# ATSAMG54x19 register map
Vendor: Atmel; Series: SAMG54; File version: 0
Atmel ATSAMG54x19 Microcontroller
CPU: CM4 r0p1, selectable endian, MPU, FPU, 4 interrupt priority bits
Registers are 32-bit, read-write, reset 0x0 unless marked. A register's access mark holds for its fields unless they carry their own. Offsets are from the block's base; lines under a group give offsets from that group; [hi:lo] are bit positions; {n}, {i} and the like mark numbered series; 'fields as' and 'values as' point back to an identical list; <NAME> marks a mode.

## Memory map
0x40000000 I2SC0 size 0x4000 — Inter-IC Sound Controller 0
0x40004000 I2SC1 size 0x4000 — Inter-IC Sound Controller 1
0x40008000 SPI size 0x4000 — Serial Peripheral Interface
0x4000D000 MPU size 0x830 — Memory Protection Unit (MPU)
0x40010000 TC0 size 0x4000 — Timer Counter 0
0x40014000 TC1 size 0x4000 — Timer Counter 1
0x40018000 TWI0 size 0x4000 — Two-wire Interface High Speed
0x4001C000 TWI1 size 0x4000 — Two-wire Interface 1
0x40024000 USART size 0x4000 — Universal Synchronous Asynchronous Receiver Transmitter
0x40028000 MEM2MEM size 0x4000 — Memory to Memory
0x4002C000 PDMIC0 size 0x4000 — Pulse Density Modulation Interface Controller 0
0x40030000 PDMIC1 size 0x4000 — Pulse Density Modulation Interface Controller 1
0x40038000 ADC size 0x4000 — Analog-to-Digital Converter
0x40040000 TWI2 size 0x4000 — Two-wire Interface 2
0x400E0200 MATRIX size 0x200 — AHB Bus Matrix
0x400E0400 PMC size 0x140 — Power Management Controller
0x400E0600 UART0 size 0x128 — Universal Asynchronous Receiver Transmitter 0
0x400E0740 CHIPID size 0x200 — Chip Identifier
0x400E0800 UART1 size 0x128 — Universal Asynchronous Receiver Transmitter 1
0x400E0A00 EFC size 0x200 — Embedded Flash Controller
0x400E0E00 PIOA size 0x200 — Parallel Input/Output Controller A
0x400E1000 PIOB size 0x200 — Parallel Input/Output Controller B
0x400E1400 RSTC size 0x200 — Reset Controller
0x400E1410 SUPC size 0x200 — Supply Controller
0x400E1430 RTT size 0x200 — Real-time Timer
0x400E1450 WDT size 0x200 — Watchdog Timer
0x400E1460 RTC size 0x200 — Real-time Clock
0x400E1490 GPBR size 0x200 — General Purpose Backup Registers
0xE000E000 SCB blocks up to offset 0xD40 — System Control Block (SCB)
0xE000E010 SYST size 0x10 — System timer, SysTick
0xE000E100 NVIC size 0xE04 — Nested Vectored Interrupt Controller (NVIC)
0xE000EF34 FPU size 0x10 — Floating Point Unit (FPU)

## Interrupts
3 INT_Hard_Fault (SCB)
4 INT_Mem_Manage_Fault (SCB)
5 INT_Bus_Fault (SCB)
5 PMC
6 EFC
6 INT_Usage_Fault (SCB)
8 UART0
9 UART1
11 INT_SVCall (SCB)
11 PIOA
12 PIOB
13 PDMIC0
14 INT_PendableSrvReq (SCB)
14 USART
15 INT_SysTick (SYST)
15 MEM2MEM
16 I2SC0
17 I2SC1
18 PDMIC1
19 TWI0
20 TWI1
21 SPI
22 TWI2
23 TC0
24 TC1 (TC0)
25 TC2 (TC0)
26 TC3 (TC1)
27 TC4 (TC1)
28 TC5 (TC1)
29 ADC

## PDMIC0 — Pulse Density Modulation Interface Controller 0
Base 0x4002C000; register names take the prefix PDMIC0_
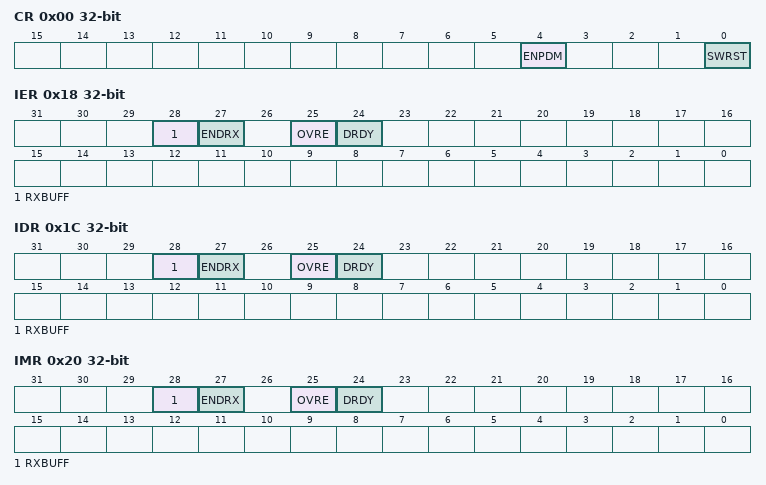
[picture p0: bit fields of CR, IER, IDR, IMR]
0x00 CR — Control Register
  [4] ENPDM — Enable PDM
  [0] SWRST — Software Reset
0x04 MR reset 0xF00000 — Mode Register
  [14:8] PRESCAL — Prescaler Rate Selection
0x14 CDR ro — Converted Data Register
  [31:0] DATA — Data Converted
0x18 IER wo reset not defined — Interrupt Enable Register
  [28] RXBUFF — Receive Buffer Full Interrupt Enable
  [27] ENDRX — End of Receive Buffer Interrupt Enable
  [25] OVRE — Overrun Error Interrupt Enable
  [24] DRDY — Data Ready Interrupt Enable
0x1C IDR wo reset not defined — Interrupt Disable Register
  [28] RXBUFF — Receive Buffer Full Interrupt Disable
  [27] ENDRX — End of Receive Buffer Interrupt Disable
  [25] OVRE — General Overrun Error Interrupt Disable
  [24] DRDY — Data Ready Interrupt Disable
0x20 IMR ro — Interrupt Mask Register
  [28] RXBUFF — Receive Buffer Full Interrupt Mask
  [27] ENDRX — End of Receive Buffer Interrupt Mask
  [25] OVRE — General Overrun Error Interrupt Mask
  [24] DRDY — Data Ready Interrupt Mask
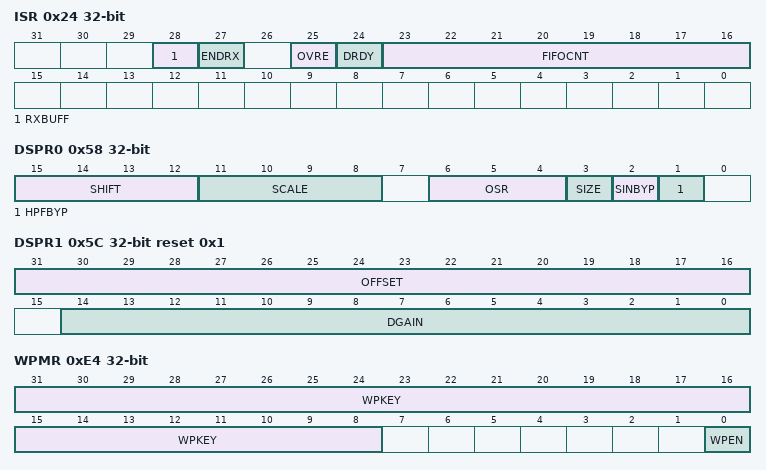
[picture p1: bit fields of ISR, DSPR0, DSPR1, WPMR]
0x24 ISR ro — Interrupt Status Register
  [28] RXBUFF — RX Buffer Full
  [27] ENDRX — End of RX Buffer
  [25] OVRE — Overrun Error
  [24] DRDY — Data Ready
  [23:16] FIFOCNT — FIFO Count
0x58 DSPR0 — DSP Configuration Register 0
  [15:12] SHIFT — Data Shift
  [11:8] SCALE — Data Scale
  [6:4] OSR — Oversampling Ratio
    0=Oversampling ratio is 128; 1=Oversampling ratio is 64
  [3] SIZE — Data Size
  [2] SINBYP — SINCC Filter Bypass
  [1] HPFBYP — High-Pass Filter Bypass
0x5C DSPR1 reset 0x1 — DSP Configuration Register 1
  [31:16] OFFSET — Offset Correction
  [14:0] DGAIN — Gain Correction
0xE4 WPMR — Write Protection Mode Register
  [31:8] WPKEY — Write Protect Key
    0x414443=PASSWD (Writing any other value in this field aborts the write operation of the WPEN bit.Always reads as 0.)
  [0] WPEN — Write Protection Enable
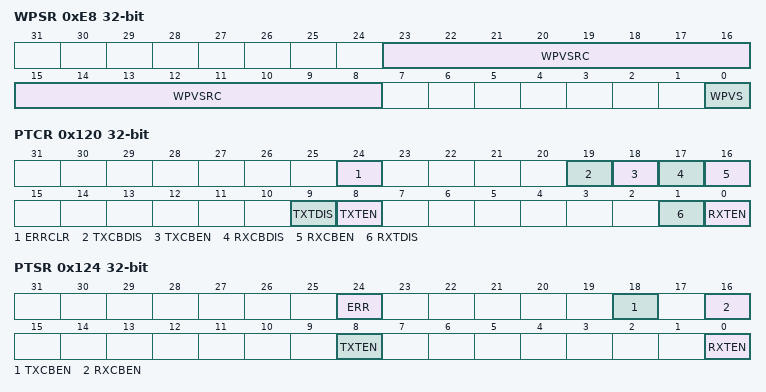
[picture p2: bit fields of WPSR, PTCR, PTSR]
0xE8 WPSR ro — Write Protection Status Register
  [23:8] WPVSRC — Write Protection Violation Source
  [0] WPVS — Write Protection Violation Status
0x100 RPR — Receive Pointer Register
  [31:0] RXPTR
0x104 RCR — Receive Counter Register
  [15:0] RXCTR
0x110 RNPR — Receive Next Pointer Register
  [31:0] RXNPTR — Receive Next Pointer
0x114 RNCR — Receive Next Counter Register
  [15:0] RXNCTR — Receive Next Counter
0x120 PTCR wo — Transfer Control Register
  [24] ERRCLR — Transfer Bus Error Clear
  [19] TXCBDIS — Transmitter Circular Buffer Disable
  [18] TXCBEN — Transmitter Circular Buffer Enable
  [17] RXCBDIS — Receiver Circular Buffer Disable
  [16] RXCBEN — Receiver Circular Buffer Enable
  [9] TXTDIS — Transmitter Transfer Disable
  [8] TXTEN — Transmitter Transfer Enable
  [1] RXTDIS — Receiver Transfer Disable
  [0] RXTEN — Receiver Transfer Enable
0x124 PTSR ro — Transfer Status Register
  [24] ERR — Transfer Bus Error
  [18] TXCBEN — Transmitter Transfer Enable
  [16] RXCBEN — Receiver Transfer Enable
  [8] TXTEN — Transmitter Transfer Enable
  [0] RXTEN — Receiver Transfer Enable

## PDMIC1 — Pulse Density Modulation Interface Controller 1
Base 0x40030000; register names take the prefix PDMIC1_
Registers as PDMIC0.

## Notices in the file
SAM Software Package License
Copyright (c) 2014, Atmel Corporation
All rights reserved.
Redistribution and use in source and binary forms, with or without
modification, are permitted provided that the following condition is met:
- Redistributions of source code must retain the above copyright notice,
this list of conditions and the disclaimer below.
Atmel's name may not be used to endorse or promote products derived from
this software without specific prior written permission.
DISCLAIMER:  THIS SOFTWARE IS PROVIDED BY ATMEL "AS IS" AND ANY EXPRESS OR
IMPLIED WARRANTIES, INCLUDING, BUT NOT LIMITED TO, THE IMPLIED WARRANTIES OF
MERCHANTABILITY, FITNESS FOR A PARTICULAR PURPOSE AND NON-INFRINGEMENT ARE
DISCLAIMED. IN NO EVENT SHALL ATMEL BE LIABLE FOR ANY DIRECT, INDIRECT,
INCIDENTAL, SPECIAL, EXEMPLARY, OR CONSEQUENTIAL DAMAGES (INCLUDING, BUT NOT
LIMITED TO, PROCUREMENT OF SUBSTITUTE GOODS OR SERVICES; LOSS OF USE, DATA,
OR PROFITS; OR BUSINESS INTERRUPTION) HOWEVER CAUSED AND ON ANY THEORY OF
LIABILITY, WHETHER IN CONTRACT, STRICT LIABILITY, OR TORT (INCLUDING
NEGLIGENCE OR OTHERWISE) ARISING IN ANY WAY OUT OF THE USE OF THIS SOFTWARE,
EVEN IF ADVISED OF THE POSSIBILITY OF SUCH DAMAGE.
